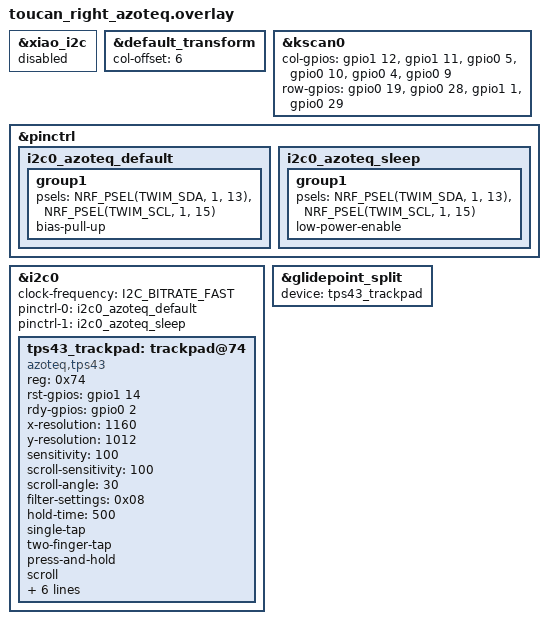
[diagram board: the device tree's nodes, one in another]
// Right half with the Toucan Upgrade Kit's Azoteq TPS43 (IQS550, I2C)
// in place of the Cirque Pinnacle (SPI). Built ALONGSIDE toucan_right —
// the cirque variant stays buildable for the revert path (AZOTEQ_UPGRADE.md).
//
// Pinout + pinctrl mirror beekeeb/zmk-keyboard-toucan2 (b3e2b84d,
// 2026-07-28): the converter board reuses the old cirque SPI pins for I2C
// (SDA=P1.13, SCL=P1.15, RST=P1.14, RDY=P0.02), trackpad at 0x74
// (BUILD_ASSERTed in the driver — not relocatable).

#include "toucan.dtsi"

// xiao_i2c is &i2c1 (P0.04/P0.05 — this overlay's kscan cols 5 and 3),
// enabled by the board dts; with CONFIG_I2C=y it would instantiate TWIM1
// and re-claim those pins via pinctrl on any PM resume. Both sibling
// overlays disable it for the same reason. The trackpad rides &i2c0.
&xiao_i2c {
    status = "disabled";
};

&default_transform {
    col-offset = <6>;
};

&kscan0 {
    col-gpios
    = <&gpio1 12 GPIO_ACTIVE_HIGH>
    , <&gpio1 11 GPIO_ACTIVE_HIGH>
    , <&gpio0 5 GPIO_ACTIVE_HIGH>
    , <&gpio0 10 GPIO_ACTIVE_HIGH>
    , <&gpio0 4 GPIO_ACTIVE_HIGH>
    , <&gpio0 9 GPIO_ACTIVE_HIGH>
    ;

    row-gpios
    = <&gpio0 19 (GPIO_ACTIVE_HIGH | GPIO_PULL_DOWN)>
    , <&gpio0 28 (GPIO_ACTIVE_HIGH | GPIO_PULL_DOWN)>
    , <&gpio1 1 (GPIO_ACTIVE_HIGH | GPIO_PULL_DOWN)>
    , <&gpio0 29 (GPIO_ACTIVE_HIGH | GPIO_PULL_DOWN)>
    ;
};

&pinctrl {
    i2c0_azoteq_default: i2c0_azoteq_default {
        group1 {
            psels = <NRF_PSEL(TWIM_SDA, 1, 13)>,
                    <NRF_PSEL(TWIM_SCL, 1, 15)>;
            bias-pull-up;
        };
    };

    i2c0_azoteq_sleep: i2c0_azoteq_sleep {
        group1 {
            psels = <NRF_PSEL(TWIM_SDA, 1, 13)>,
                    <NRF_PSEL(TWIM_SCL, 1, 15)>;
            low-power-enable;
        };
    };
};

&i2c0 {
    status = "okay";
    clock-frequency = <I2C_BITRATE_FAST>;
    pinctrl-0 = <&i2c0_azoteq_default>;
    pinctrl-1 = <&i2c0_azoteq_sleep>;
    pinctrl-names = "default", "sleep";

    tps43_trackpad: trackpad@74 {
        compatible = "azoteq,tps43";
        reg = <0x74>;
        status = "okay";

        rst-gpios = <&gpio1 14 GPIO_ACTIVE_HIGH>;
        rdy-gpios = <&gpio0 2 GPIO_ACTIVE_HIGH>;

        // Cursor speed: tuned via ON-CHIP resolution, the only
        // azoteq-only knob with no integer-truncation dead zone —
        // driver sensitivity <100 is stateless division (1-count deltas
        // vanish), and v0.3 peripheral-side split processors get no
        // remainder state either. 2026-08-20 trial feedback: 2.25x felt
        // "really fast", so target beekeeb-reference feel: assumed
        // default 2048x1792 (upstream README values) / 2.25. If still
        // off, adjust these absolute values — deterministic from here.
        // Chip gesture-distance defaults (tap-distance etc.) are in
        // resolution px, so they got physically bigger; if taps/
        // scroll-start feel sloppy, set tap-distance /
        // scroll-initial-distance explicitly to compensate.
        // SCALER CONSOLIDATION (2026-08-20 pm): the central 2.25x XY
        // upscale is GONE (toucan.dtsi) — resolution here is now the
        // whole speed calibration, at ~1px per count instead of ~2.25px
        // (v13's slow-movement jitter was that quantization). 1160x1012
        // = 515x450 (the speed Kolter approved) x 2.25 — NET SPEED
        // UNCHANGED from v13.
        // Speed-cut history (in old post-scaler terms): 910x796 ->
        // 730x640 -> 620x544 -> 515x450, each on trial feedback.
        // COUPLING NOTE: on-chip gesture distances (tap-distance,
        // scroll-initial-distance) are in resolution px — this ~2.25x
        // raise makes their defaults physically TIGHTER. If taps start
        // getting rejected (finger wiggle disqualifies them) or scroll
        // engages too eagerly, set tap-distance / scroll-initial-distance
        // explicitly (~2.25x their defaults).
        x-resolution = <1160>;
        y-resolution = <1012>;

        // Keep 100: <100 dead-zones slow precise movement (see above).
        sensitivity = <100>;
        // Explicit: binding default (50) and C fallback (100) disagree.
        // Wheel is scaled 1/20 on the left listener instead (no
        // truncation at the source).
        scroll-sensitivity = <100>;

        // beekeeb's toucan2 tuning (default ~47deg scroll cone too big)
        scroll-angle = <30>;
        // Filter experiments:
        // 0x0B (beekeeb: IIR + MAV + ALP) -> 0x09 (2026-08-20, dropped
        // MAV: cured the steady-state float) -> 0x08 (v11 feedback:
        // intermittent float returned, now at SLOW speeds too — the
        // dynamic IIR's speed thresholds are in counts/cycle, and our
        // resolution cuts (now ~28% of native scale) push nearly all
        // movement under its "slow = smooth heavily" threshold).
        // 0x08 = ALP count filter only, NO XY position filtering.
        // If slow-movement jitter appears: the fix is the scaler
        // consolidation (native-scale resolution restores the filter's
        // designed regime, so IIR can return) — not re-adding filters
        // at this resolution.
        filter-settings = <0x08>;
        hold-time = <500>;

        // Gestures (swipes / three-finger-swipe still deferred — they
        // need a swipe_button_mapper on the central; see
        // AZOTEQ_UPGRADE.md open decisions).
        single-tap;
        two-finger-tap;
        press-and-hold;
        scroll;
        // Pinch-zoom: chip emits REL_MISC deltas; the central's
        // zip_zoom_mapper (toucan.dtsi, zmk-input-zoom module) converts
        // them to Ctrl+Minus / Ctrl+Equal — Chrome/Windows browser zoom
        // steps, not smooth pinch (added 2026-08-20, trial feedback).
        zoom;

        switch-xy;
        invert-scroll-y;

        enable-power-management;
        // idle-sleep deliberately OFF: same 300ms wake-lag tradeoff we
        // rejected on the cirque; beekeeb marks it "not recommended" too.
        // (Verified in tps43_idle_sleeper.c: without idle-sleep, ZMK's
        // 30s IDLE state does NOT touch the pad — the after-idle wake
        // lag is purely the chip's own LP ladder, tuned below.)
        //
        // Wake-lag fix (2026-08-20, "delay after sitting is really
        // bad"): stay in LP1 (fast wake) for 100s before dropping to
        // LP2 (register is 20s units), and sample LP2 at 320ms instead
        // of 640ms so the worst-case first-touch delay after a long
        // sit is ~0.3s. Cost: ~110uA in LP2 vs 55uA — negligible.
        timeout-lp1 = <5>;
        report-rate-lp2 = <320>;
    };
};

// Same split-input endpoint (reg 0) the cirque feeds — the left half
// doesn't know or care which pad is on the other end, so ONE left
// firmware serves both right-half variants.
&glidepoint_split {
    device = <&tps43_trackpad>;
};
